# V32F20x_CM33 register map
File version: 1.0.3
CPU: CM33 r0p4, little endian, MPU, FPU, DSP, 3 interrupt priority bits, 8 SAU regions
Registers are 32-bit, read-write, reset 0x0 unless marked. A register's access mark holds for its fields unless they carry their own. Offsets are from the block's base; [hi:lo] are bit positions; {n}, {i} and the like mark numbered series; 'fields as' and 'values as' point back to an identical list.

## SDIO0 — SDIO0 Peripheral Interface
Base 0x40084000
Same registers: SDIO1 0x40086000, SEC_SDIO0 0x50084000, SEC_SDIO1 0x50086000
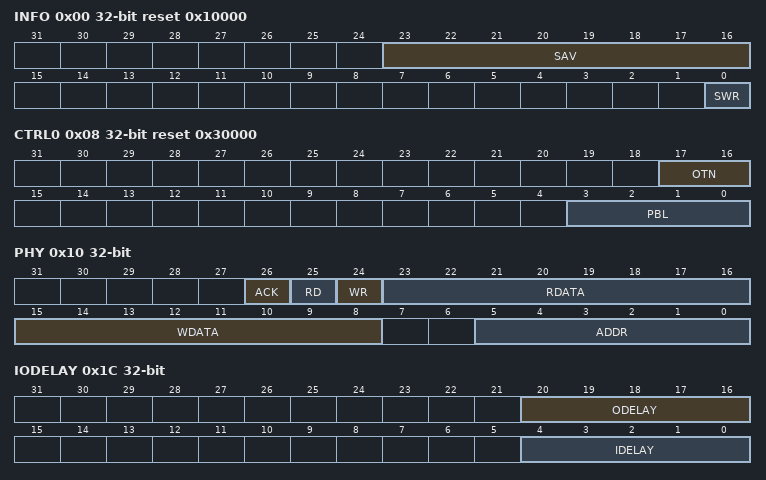
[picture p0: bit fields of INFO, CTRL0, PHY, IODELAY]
0x00 INFO reset 0x10000 — General Information Register
  [23:16] SAV — Slot Available
  [0] SWR — Software Reset
0x04 DEBOUNCE reset 0x32 — De-bounce Setting Register
  [23:0] DP — De-bounce Period
0x08 CTRL0 reset 0x30000
  [17:16] OTN — Number of Outstanding Transfers
  [3:0] PBL — Programmable Burst Length
0x10 PHY — PHY Registers Interface
  [26] ACK — PHY Transaction Acknowledge
  [25] RD — PHY Read Transaction Request
  [24] WR — PHY Write Transaction Requests
  [23:16] RDATA — PHY Read Data
  [15:8] WDATA — PHY Write Data
  [5:0] ADDR — PHY Register Address
0x18 MODE — control registers
  [2:0] EMM — Mode select
0x1C IODELAY — IO Delay Information Register
  [20:16] ODELAY — Output delay value for IO.
  [4:0] IDELAY — Input delay value for IO.
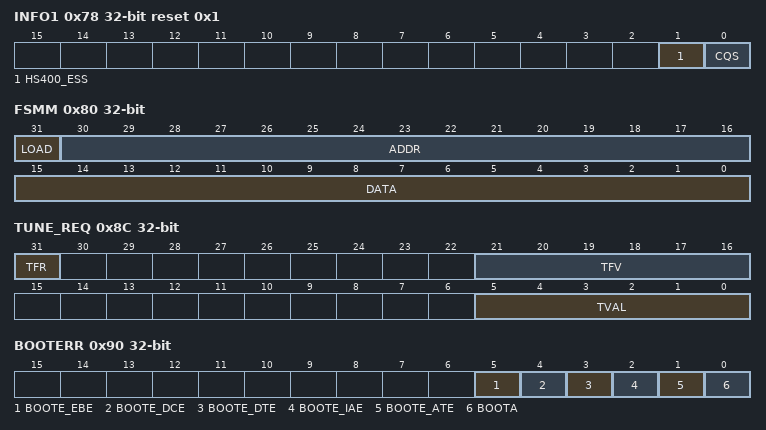
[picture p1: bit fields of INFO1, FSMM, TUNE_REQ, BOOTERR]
0x78 INFO1 reset 0x1 — Host Capability Register
  [1] HS400_ESS — High Speed 400 Enhance Strobe supported
  [0] CQS — Command Queuing supported
0x80 FSMM — FSM Monitor Register
  [31] LOAD — FSM monitor update request
  [30:16] ADDR — FSM address
  [15:0] DATA — FSM status
0x84 STATUS0 — Tune Status 0 Register
  [31:0] STAT0 — Tune status 0
0x88 STATUS1 — Tune Status 1 Register
  [7:0] STAT1 — Tune status 1
0x8C TUNE_REQ — Tune Debug Register
  [31] TFR — Tune Force Request
  [21:16] TFV — Tune Force Value
  [5:0] TVAL — Tune Current Value
0x90 BOOTERR — Boot Status Register
  [5] BOOTE_EBE — Boot Error - End Bit Error
  [4] BOOTE_DCE — Boot Error - Data CRC Error
  [3] BOOTE_DTE — Boot Error - Data Timeout Error
  [2] BOOTE_IAE — Boot Error - Invalid Acknowledge Error
  [1] BOOTE_ATE — Boot Error - Acknowledge Timeout Error
  [0] BOOTA — Boot Active
0x94 SPEED — Read block gap coefficient interface mode select
  [5:0] RGB_COEFF_IFM — Read Block Gap Coefficient
0x98 RBGC — Read block gap coefficient
  [3:0] RBGC — Read block gap coefficient.
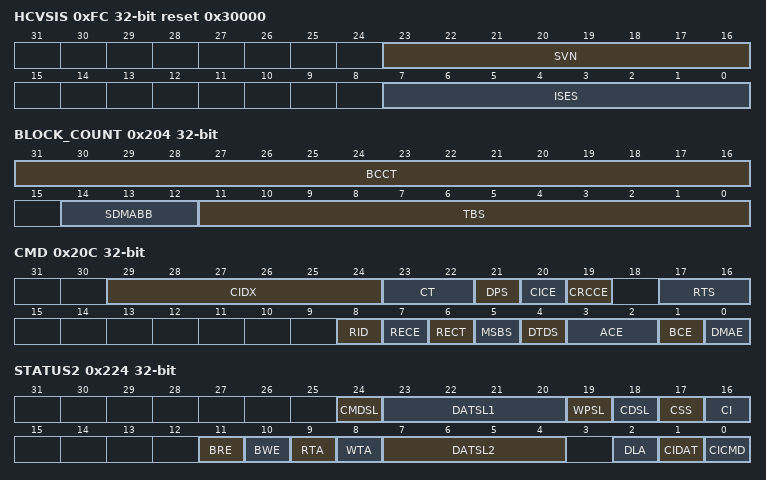
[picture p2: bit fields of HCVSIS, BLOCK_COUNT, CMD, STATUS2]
0xFC HCVSIS ro reset 0x30000 — Host Controller Version/Slot Interrupt Status
  [23:16] SVN — Specification Version Number.
  [7:0] ISES — Interrupt Signal For Each Slot.
0x200 ADDR — SDMA System Address / Argument 2
  [31:0] SAAR — System Address / Argument 2 This field is used as:
0x204 BLOCK_COUNT — Block Size / Block Count
  [31:16] BCCT — Block Count For Current Transfer
  [14:12] SDMABB — SDMA Buffer Boundary
  [11:0] TBS — Transfer Block Size
0x208 ARG — Argument 1
  [31:0] ARG1 — Command Argument 1
0x20C CMD — Command/Transfer Mode
  [29:24] CIDX — Command Index
  [23:22] CT — Command Type
  [21] DPS — Data Present Select
  [20] CICE — Command Index Check Enable
  [19] CRCCE — Command CRC Check Enable
  [17:16] RTS — Response Type Select
  [8] RID — Response Interrupt Disable
  [7] RECE — Response Error Check Enable
  [6] RECT — Response Type R1/R5
  [5] MSBS — Multi/Single Block Select
  [4] DTDS — Data Transfer Direction Select
  [3:2] ACE — Auto CMD Enable
  [1] BCE — Block Count Enable
  [0] DMAE — DMA Enable
0x210 RESP1 ro — Response returned by the card
  [31:0] RESP1 — The RESP1 RESP4 registers store the response returned by the card
{0x20C+4i} RESP{i} ro (i=2..4) — Response returned by the card
  [31:0] RESP{i} — RESP{i} - Response Register #{i}
0x220 DATA — Buffer Data Port
  [31:0] BDP
0x224 STATUS2 ro — Present State Register
  [24] CMDSL — CMD Line Signal Level (SD Mode only)
  [23:20] DATSL1 — DAT[3:0] Line Signal Level (SD Mode only)
  [19] WPSL — Write Protect Switch Pin Level
  [18] CDSL — Card Detect Pin Level
  [17] CSS — Card State Stable
  [16] CI — Card Inserted
  [11] BRE — Buffer Read Enable
  [10] BWE — Buffer Write Enable
  [9] RTA — Read Transfer Active (SD Mode only)
  [8] WTA — Write Transfer Active (SD Mode only)
  [7:4] DATSL2 — DAT[7:4] Line Signal Level (SD Mode only)
  [2] DLA — DAT Line Active (SD Mode only)
  [1] CIDAT — Command Inhibit DAT (SD Mode only)
  [0] CICMD — Command Inhibit CMD
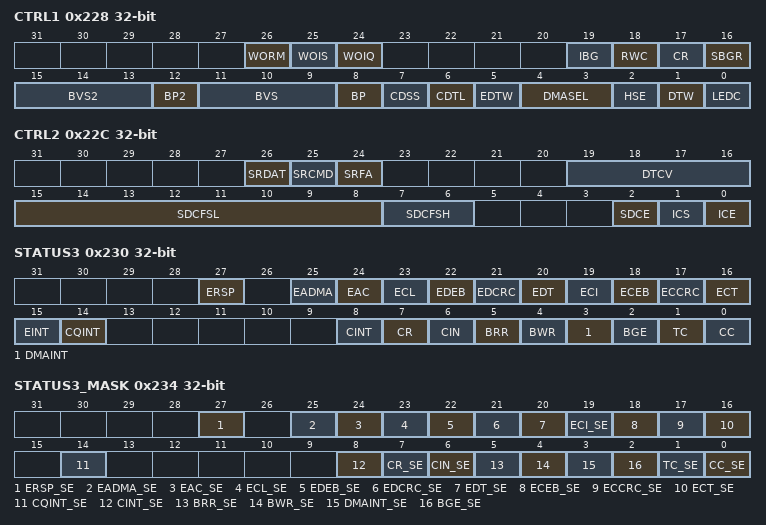
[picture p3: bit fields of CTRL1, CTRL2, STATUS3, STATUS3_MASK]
0x228 CTRL1 — Host Control 1 (General / Power / Block-Gap / Wake-Up)
  [26] WORM — Wakeup Event Enable On SD Card Removal
  [25] WOIS — Wake-Up Event Enable On Card Inserted
  [24] WOIQ — Wakeup Event Enable On Card Interrupt
  [19] IBG — Interrupt At Block Gap (SD Mode only)
  [18] RWC — Read-Wait Control (SD Mode only)
  [17] CR — Continue Request
  [16] SBGR — Stop At Block Gap Request
  [15:13] BVS2 — SD Bus Voltage Select for VDD2
  [12] BP2 — SD Bus Power for VDD2
  [11:9] BVS — SD Bus Voltage Select
  [8] BP — SD Bus Power for VDD1
  [7] CDSS — Card Detect Signal Selection
  [6] CDTL — Card Detect Test Level
  [5] EDTW — Extended Data Transfer Width
  [4:3] DMASEL — DMA Select
  [2] HSE — High Speed Enable (SD mode only)
  [1] DTW — Data Transfer Width (SD mode only)
  [0] LEDC — LED Control
0x22C CTRL2 — Host Control 2 (Clock, Timeout, Reset)
  [26] SRDAT — Software Reset For DAT Line (SD Mode only)
  [25] SRCMD — Software Reset For CMD Line (SD Mode only)
  [24] SRFA — Software Reset For All
  [19:16] DTCV — Data Timeout Counter Value
  [15:8] SDCFSL — SDCLK Frequency Select (lower part)
  [7:6] SDCFSH — SDCLK Frequency Select (higher part)
  [2] SDCE — SD Clock Enable
  [1] ICS — Internal Clock Stable
  [0] ICE — Internal Clock Enable
0x230 STATUS3 — Error/Normal Interrupt Status
  [27] ERSP — Response Error (SD Mode only)
  [25] EADMA — ADMA Error
  [24] EAC — Generated when an error occurs during Auto
  [23] ECL — Current Limit Error
  [22] EDEB — Data End Bit Error (SD mode only)
  [21] EDCRC — Data CRC Error (SD mode only)
  [20] EDT — Data Timeout Error (SD mode only)
  [19] ECI — Command Index Error (SD mode only)
  [18] ECEB — Command End Bit Error (SD mode only)
  [17] ECCRC — Command CRC Error (SD mode only)
  [16] ECT — Command Timeout Error (SD mode only)
  [15] EINT — Error Interrupt
  [14] CQINT — Command Queuing Interrupt
  [8] CINT — Card Interrupt
  [7] CR — Card Removal
  [6] CIN — Card Insertion
  [5] BRR — Buffer Read Ready
  [4] BWR — Buffer Write Ready
  [3] DMAINT — DMA Interrupt
  [2] BGE — Block Gap Event
  [1] TC — Transfer Complete
  [0] CC — Command Complete
0x234 STATUS3_MASK — Error/Normal Status Enable
  [27] ERSP_SE — Response Error Status Enable (SD mode only)
  [25] EADMA_SE — ADMA Error Status Enable (SD mode only)
  [24] EAC_SE — Auto CMD Error Status Enable (SD mode only)
  [23] ECL_SE — Current Limit Error Status Enable (SD mode only)
  [22] EDEB_SE — Data End Bit Error Status Enable (SD mode only)
  [21] EDCRC_SE — Data CRC Error Status Enable (SD mode only)
  [20] EDT_SE — Data Timeout Error Status Enable (SD mode only)
  [19] ECI_SE — Command Index Error Status Enable (SD mode only)
  [18] ECEB_SE — Command End Bit Error Status Enable (SD mode only)
  [17] ECCRC_SE — Command CRC Error Status Enable (SD mode only)
  [16] ECT_SE — Command Timeout Error Status Enable SD mode only
  [14] CQINT_SE — Command Queuing Status Enable
  [8] CINT_SE — Card Interrupt Status Enable
  [7] CR_SE — Card Removal Status Enable
  [6] CIN_SE — Card Insertion Status Enable
  [5] BRR_SE — Buffer Read Ready Status Enable
  [4] BWR_SE — Buffer Write Ready Status Enable
  [3] DMAINT_SE — DMA Interrupt Status Enable
  [2] BGE_SE — Block Gap Event Status Enable
  [1] TC_SE — Transfer Complete Status Enable
  [0] CC_SE — Command Complete Status Enable
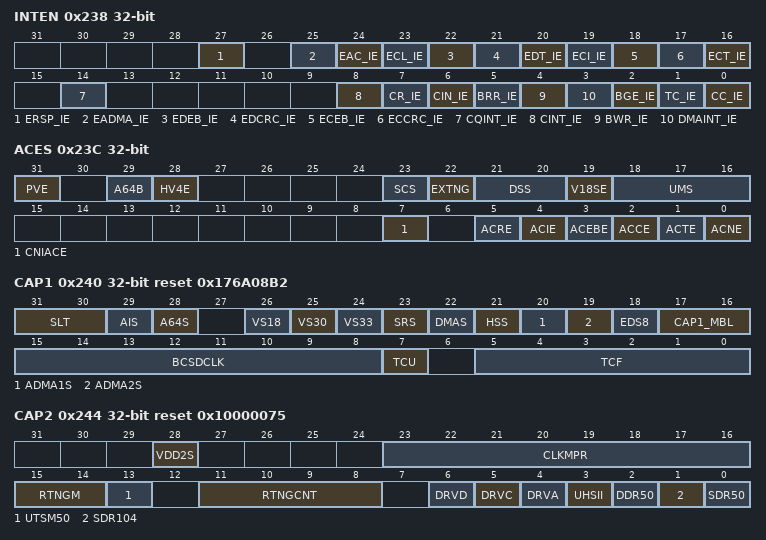
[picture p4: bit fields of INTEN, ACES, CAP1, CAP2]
0x238 INTEN — Error/Normal Signal Enable Interrupt Enable
  [27] ERSP_IE — Response Error Interrupt Enable
  [25] EADMA_IE — ADMA Error Interrupt Enable (SD mode only)
  [24] EAC_IE — Auto CMD Error Interrupt Enable (SD mode only)
  [23] ECL_IE — Current Limit Error Interrupt Enable SD mode only
  [22] EDEB_IE — Data End Bit Error Interrupt Enable (SD mode only)
  [21] EDCRC_IE — Data CRC Error Interrupt Enable (SD mode only)
  [20] EDT_IE — Data Timeout Error Interrupt Enable (SD mode only)
  [19] ECI_IE — Command Index Error Interrupt Enable SD mode only
  [18] ECEB_IE — Command End Bit Error Interrupt Enable (SD
  [17] ECCRC_IE — Command CRC Error Interrupt Enable (SD mode only)
  [16] ECT_IE — Command Timeout Error Interrupt Enable SD mode only
  [14] CQINT_IE — Command Queuing - Interrupt Enable
  [8] CINT_IE — Card Interrupt - Interrupt Enable
  [7] CR_IE — Card Removal Interrupt Enable
  [6] CIN_IE — Card Insertion Interrupt Enable
  [5] BRR_IE — Buffer Read Ready Interrupt Enable
  [4] BWR_IE — Buffer Write Ready Interrupt Enable
  [3] DMAINT_IE — DMA Interrupt Enable
  [2] BGE_IE — Block Gap Event Interrupt Enable
  [1] TC_IE — Transfer Complete Interrupt Enable
  [0] CC_IE — Command Complete Interrupt Enable
0x23C ACES — Host Control 2 / Auto CMD Error Status
  [31] PVE — Preset Value Enable
  [29] A64B — 64-bit Addressing
  [28] HV4E — Host Version 4.00 Enable
  [23] SCS — Sampling Clock Select (UHS-I only)
  [22] EXTNG — Execute Tuning (UHS-I only)
  [21:20] DSS — Driver Strength Select (UHS-I only)
  [19] V18SE — 1.8V Signaling Enable (UHS-I only)
  [18:16] UMS — UHS Mode Select
  [7] CNIACE — Command Not Issued By Auto CMD12 Error
  [5] ACRE — Auto CMD Response Error
  [4] ACIE — Auto CMD Index Error
  [3] ACEBE — Auto CMD End Bit Error
  [2] ACCE — Auto CMD CRC Error
  [1] ACTE — Auto CMD Timeout Error
  [0] ACNE — Auto CMD12 Not Executed
0x240 CAP1 reset 0x176A08B2 — Capabilities 1
  [31:30] SLT — Slot Type
  [29] AIS — Asynchronous Interrupt Support
  [28] A64S — 64-bit System Addressing Support
  [26] VS18 — Voltage Support 1.8V
  [25] VS30 — Voltage Support 3.0V
  [24] VS33 — Voltage Support 3.3V
  [23] SRS — Suspend / Resume Support
  [22] DMAS — SDMA Support
  [21] HSS — High Speed Support
  [20] ADMA1S — ADMA1 Support
  [19] ADMA2S — ADMA2 Support
  [18] EDS8 — 8-bit Embedded Device Support
  [17:16] CAP1_MBL — Max Block Length
  [15:8] BCSDCLK — Base Clock Frequency for SD Clock
  [7] TCU — Timeout Clock Unit
  [5:0] TCF — Timeout Clock Frequency
0x244 CAP2 reset 0x10000075 — Capabilities 2
  [28] VDD2S — VDD2 Supported
  [23:16] CLKMPR — Clock Multiplier
  [15:14] RTNGM — Re-Tuning Modes
  [13] UTSM50 — Use Tuning for SDR50
  [11:8] RTNGCNT — Timer Count for Re-Tuning
  [6] DRVD — 1.8V Line Driver Type D Supported
  [5] DRVC — 1.8V Line Driver Type C Supported
  [4] DRVA — 1.8V Line Driver Type A Supported
  [3] UHSII — UHS-II Supported
  [2] DDR50 — DDR50 Supported
  [1] SDR104 — SDR104 Supported
  [0] SDR50 — SDR50 Supported
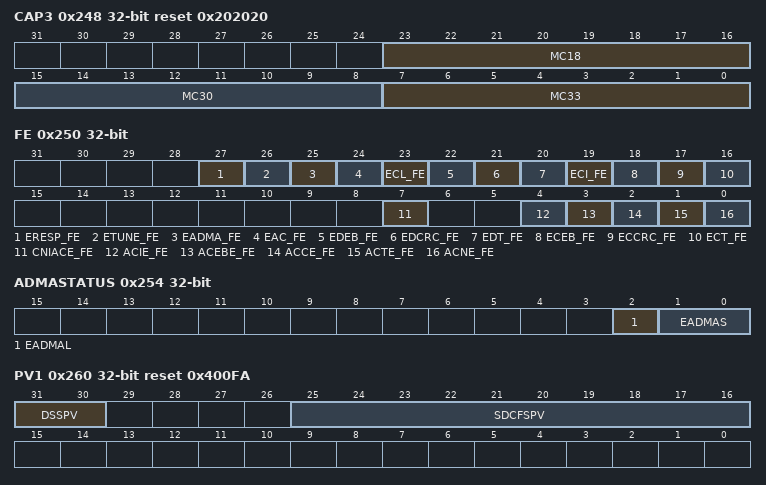
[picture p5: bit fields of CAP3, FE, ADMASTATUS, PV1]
0x248 CAP3 reset 0x202020 — Capabilities 3
  [23:16] MC18 — Maximum Current for 1.8V
  [15:8] MC30 — Maximum Current for 3.0V
  [7:0] MC33 — Maximum Current for 3.3V
0x24C CAP4 reset 0x20 — Capabilities 4
  [7:0] MC18V2 — Maximum Current for 1.8V VDD2
0x250 FE — Force Event
  [27] ERESP_FE — Force Response Error Event
  [26] ETUNE_FE — Force Tuning Error Event
  [25] EADMA_FE — Force ADMA Error Event
  [24] EAC_FE — Force Auto CMD Error Event
  [23] ECL_FE — Force Current Limit Error Event
  [22] EDEB_FE — Force Data End Bit Error Event
  [21] EDCRC_FE — Force Data CRC Error Event
  [20] EDT_FE — Force Data Timeout Error Event
  [19] ECI_FE — Force Command Index Error Event
  [18] ECEB_FE — Force Command End Bit Error Event
  [17] ECCRC_FE — Force Command CRC Error Event
  [16] ECT_FE — Force Command Timeout Error Event
  [7] CNIACE_FE — Force Command Not Issued By Auto CMD12 Error Event
  [4] ACIE_FE — Force Auto CMD Index Error Event
  [3] ACEBE_FE — Force Auto CMD End Bit Error Event
  [2] ACCE_FE — Force Auto CMD CRC Error Event
  [1] ACTE_FE — Force Auto CMD Timeout Error Event
  [0] ACNE_FE — Force Auto CMD12 Not Executed Event
0x254 ADMASTATUS — ADMA Error Status
  [2] EADMAL — ADMA Length Mismatch Error This bit is set when:
  [1:0] EADMAS — ADMA Error State
0x258 DMAADDR1 — ADMA/SDMA System Address 1
  [31:0] DMASA1 — ADMA System Address
0x25C DMAADDR2 — ADMA/SDMA System Address 2
  [31:0] DMASA2 — ADMA System Address #2
0x260 PV1 reset 0x400FA — Preset Value (Default Speed)
  [31:30] DSSPV — Driver Strength Select
  [25:16] SDCFSPV — SDCLK Clock Frequency Select
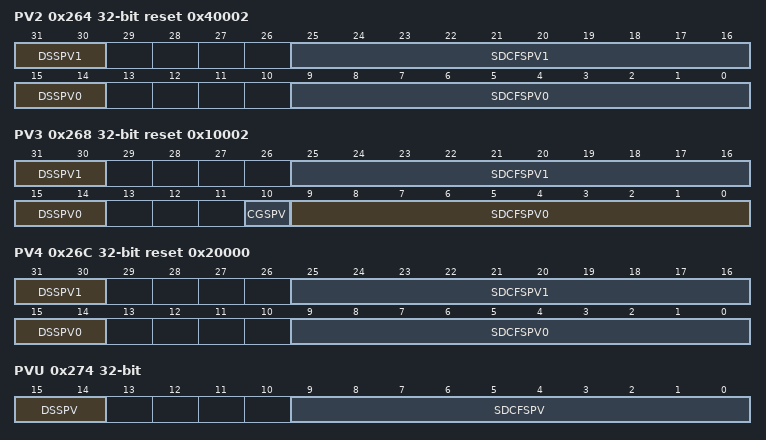
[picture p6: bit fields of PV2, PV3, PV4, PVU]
0x264 PV2 reset 0x40002 — Preset Value (High Speed and SDR12)
  [31:30] DSSPV1 — Driver Strength Select
  [25:16] SDCFSPV1 — SDCLK Clock Frequency Select
  [15:14] DSSPV0 — Driver Strength Select
  [9:0] SDCFSPV0 — SDCLK Clock Frequency Select
0x268 PV3 reset 0x10002 — Preset Value (SDR25 and SDR50)
  [31:30] DSSPV1 — Driver Strength Select
  [25:16] SDCFSPV1 — SDCLK Clock Frequency Select
  [15:14] DSSPV0 — Driver Strength Select
  [10] CGSPV — Clock Generator Select
  [9:0] SDCFSPV0 — SDCLK Clock Frequency Select
0x26C PV4 reset 0x20000 — Preset Value (SDR104 and DDR50)
  fields as PV2
0x274 PVU — Preset Value for UHS-II
  [15:14] DSSPV — Driver Strength Select
  [9:0] SDCFSPV — SDCLK Clock Frequency Select
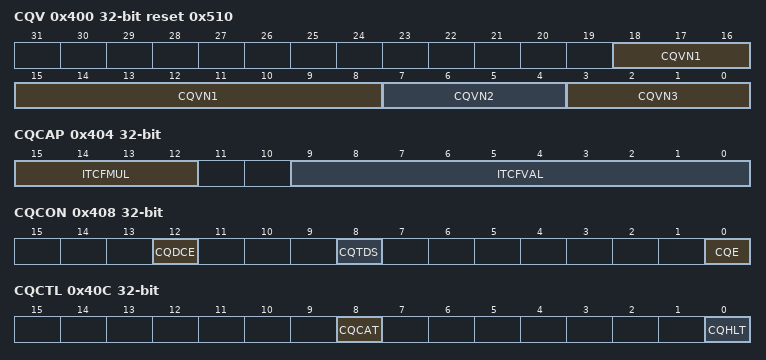
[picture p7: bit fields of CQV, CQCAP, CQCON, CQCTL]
0x400 CQV reset 0x510 — Command Queuing Version
  [18:8] CQVN1 — eMMC Major Version Number
  [7:4] CQVN2 — eMMC Minor Version Number
  [3:0] CQVN3 — eMMC Version Suffix
0x404 CQCAP — Command Queuing Capabilities
  [15:12] ITCFMUL — Internal Timer Clock Frequency Multiplier ITCFMUL
  [9:0] ITCFVAL — Internal Timer Clock Frequency Value (ITCFVAL)
0x408 CQCON — Command Queuing Configuration
  [12] CQDCE — Direct Command (DCMD) Enable
  [8] CQTDS — Task Descriptor
  [0] CQE — Command Queuing Enable
0x40C CQCTL — SD_CQCTL
  [8] CQCAT — Clear All Tasks
  [0] CQHLT — Halt CQ
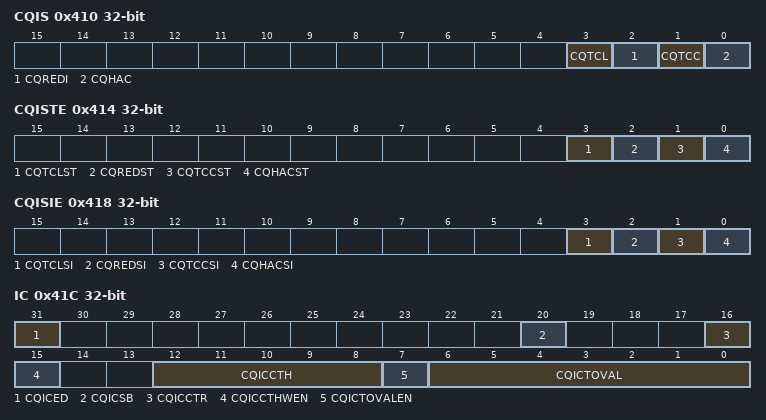
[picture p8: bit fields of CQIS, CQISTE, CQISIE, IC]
0x410 CQIS — Command Queuing Interrupt Status
  [3] CQTCL — Task Cleared (TCL)
  [2] CQREDI — Response Error Detected Interrupt (RED)
  [1] CQTCC — Task Complete Interrupt (TCC)
  [0] CQHAC — Halt Complete Interrupt (HAC)
0x414 CQISTE — Command Queuing Interrupt Status Enable
  [3] CQTCLST — Task Cleared Status Enable (TCL)
  [2] CQREDST — Response Error Detected Status Enable (RED)
  [1] CQTCCST — Task Complete Status Enable (TCC)
  [0] CQHACST — Halt Complete Status Enable (HAC)
0x418 CQISIE — Command Queuing Interrupt Signal Enable
  [3] CQTCLSI — Task Cleared Signal Enable (TCL)
  [2] CQREDSI — Response Error Detected Signal Enable (TCC)
  [1] CQTCCSI — Task Complete Signal Enable (TCC)
  [0] CQHACSI — Halt Complete Signal Enable (HAC)
0x41C IC — Interrupt Coalescing
  [31] CQICED — Interrupt Coalescing Enable/Disable
  [20] CQICSB — Interrupt Coalescing Status Bit (ICSB)
  [16] CQICCTR — Counter and Timer Reset(ICCTR)
  [15] CQICCTHWEN — Interrupt Coalescing Counter Threshold Write
  [12:8] CQICCTH — Interrupt Coalescing Counter Threshold ICCTH CQE increments internal counter when task with INT 0 is completed
  [7] CQICTOVALEN — Interrupt Coalescing Timeout Value Write Enable ICTOVALWEN
  [6:0] CQICTOVAL — Interrupt Coalescing Timeout Value (ICTOVAL)
0x420 CQTDLBA — Command Queuing Task Descriptor List Base Address
  [31:0] CQTDLBA — Task Descriptor List Base Address (lower)
0x424 CQTDLBAU — Command Queuing Task Descriptor List Base Address Upper 32 Bits
  [31:0] CQTDLBAU — Task Descriptor List Base Address (upper)
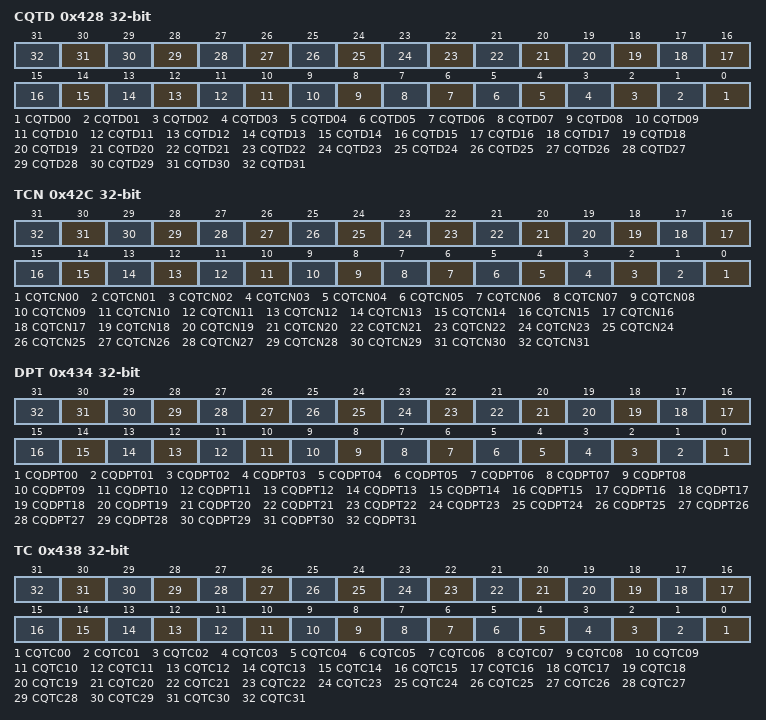
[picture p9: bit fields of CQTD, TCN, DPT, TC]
0x428 CQTD — Command Queuing Task Doorbell
  [n] CQTD{n:02} (n=0..31) — Command Queuing Task Doorbell #{n:02}
0x42C TCN — Task Complete Notification
  [n] CQTCN{n:02} (n=0..31) — Task Completion Notification #{n:02}
0x430 DQS — Device Queue Status
  [31:0] CQDQS
0x434 DPT — Device Pending Tasks
  [n] CQDPT{n:02} (n=0..31) — Device Pending Tasks #{n:02}
0x438 TC — Task Clear
  [n] CQTC{n:02} (n=0..31) — Command Queuing Task Clear #{n:02}
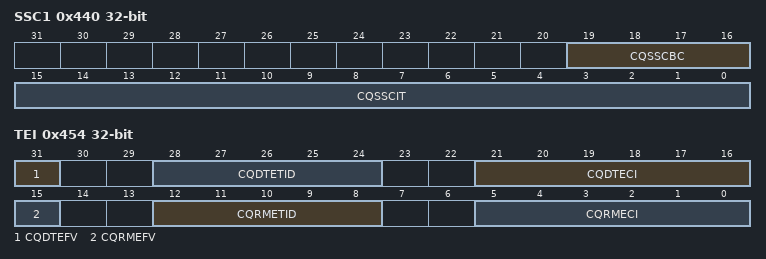
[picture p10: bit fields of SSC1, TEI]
0x440 SSC1 wo — Send Status Configuration 1
  [19:16] CQSSCBC — Send Status Command Block Counter (CBC)
  [15:0] CQSSCIT — Send Status Command Idle Timer (CIT)
0x444 SSC2 — Send Status Configuration 2
  [15:0] CQSQSR — Send Queue Status RCA
0x448 CRDCT — Command Response for Direct Command Task
  [31:0] CQDCLR — Direct Command Last Response
0x450 RMEM — Response Mode Error Mask
  [31:0] CQRMEM
0x454 TEI — Task Error Information
  [31] CQDTEFV — Data Transfer Error Fields Valid
  [28:24] CQDTETID — Data Transfer Error Task ID
  [21:16] CQDTECI — Data Transfer Error Command Index
  [15] CQRMEFV — Response Mode Error Fields Valid
  [12:8] CQRMETID — Response Mode Error Task ID
  [5:0] CQRMECI — Response Mode Error Command Index
0x458 CRI — Command Response Index
  [5:0] CQLCRI — Last Command Response Index
0x45C CRA — Command Response Argument
  [31:0] CQLCRA — Last Command Response Argument
